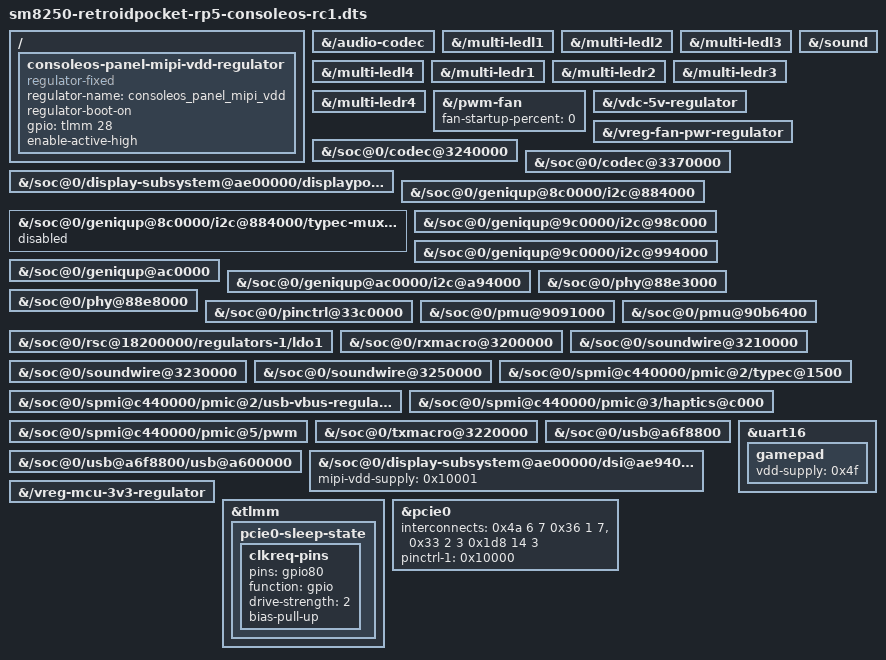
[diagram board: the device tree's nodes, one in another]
// SPDX-License-Identifier: BSD-3-Clause
/*
 * ConsoleOS RP5 release-candidate device tree.
 *
 * Start from the strict Phase 4A wireless + ADSP/PCIe-DRV source tree, then
 * enable exactly the peripherals present in the accepted Phase 4AT full-stack
 * DTB.  The sole power-policy delta is making the shared MCU/RGB/gamepad rail
 * controllable; userspace may then execute the validated Phase 4BE lifecycle.
 */

#include "sm8250-retroidpocket-rp5-phase4a-wireless-adsp-pcie-drv.dts"

/ {
	consoleos-panel-mipi-vdd-regulator {
		/* Keep every inherited RP5 phandle stable across this one-node delta. */
		phandle = <0x10001>;
		compatible = "regulator-fixed";
		regulator-name = "consoleos_panel_mipi_vdd";
		regulator-boot-on;
		gpio = <&tlmm 28 GPIO_ACTIVE_HIGH>;
		enable-active-high;
	};
};

&{/audio-codec} { status = "okay"; };
&{/multi-ledl1} { status = "okay"; };
&{/multi-ledl2} { status = "okay"; };
&{/multi-ledl3} { status = "okay"; };
&{/multi-ledl4} { status = "okay"; };
&{/multi-ledr1} { status = "okay"; };
&{/multi-ledr2} { status = "okay"; };
&{/multi-ledr3} { status = "okay"; };
&{/multi-ledr4} { status = "okay"; };
&{/pwm-fan} {
	status = "okay";
	/* Avoid ROCKNIX's fixed PWM 70 probe pulse on this handheld. */
	fan-startup-percent = <0>;
};
&{/sound} { status = "okay"; };
&{/vdc-5v-regulator} { status = "okay"; };
&{/vreg-fan-pwr-regulator} { status = "okay"; };

&{/soc@0/codec@3240000} { status = "okay"; };
&{/soc@0/codec@3370000} { status = "okay"; };
&{/soc@0/display-subsystem@ae00000/displayport-controller@ae90000} { status = "okay"; };
&{/soc@0/geniqup@8c0000/i2c@884000} { status = "okay"; };
&{/soc@0/geniqup@8c0000/i2c@884000/typec-mux@1c} { status = "disabled"; };
&{/soc@0/geniqup@9c0000/i2c@98c000} { status = "okay"; };
&{/soc@0/geniqup@9c0000/i2c@994000} { status = "okay"; };
&{/soc@0/geniqup@ac0000} { status = "okay"; };
&{/soc@0/geniqup@ac0000/i2c@a94000} { status = "okay"; };
&{/soc@0/phy@88e3000} { status = "okay"; };
&{/soc@0/phy@88e8000} { status = "okay"; };
&{/soc@0/pinctrl@33c0000} { status = "okay"; };
&{/soc@0/pmu@9091000} { status = "okay"; };
&{/soc@0/pmu@90b6400} { status = "okay"; };
&{/soc@0/rsc@18200000/regulators-1/ldo1} { status = "okay"; };
&{/soc@0/rxmacro@3200000} { status = "okay"; };
&{/soc@0/soundwire@3210000} { status = "okay"; };
&{/soc@0/soundwire@3230000} { status = "okay"; };
&{/soc@0/soundwire@3250000} { status = "okay"; };
&{/soc@0/spmi@c440000/pmic@2/typec@1500} { status = "okay"; };
&{/soc@0/spmi@c440000/pmic@2/usb-vbus-regulator@1100} { status = "okay"; };
&{/soc@0/spmi@c440000/pmic@3/haptics@c000} { status = "okay"; };
&{/soc@0/spmi@c440000/pmic@5/pwm} { status = "okay"; };
&{/soc@0/txmacro@3220000} { status = "okay"; };
&{/soc@0/usb@a6f8800} { status = "okay"; };
&{/soc@0/usb@a6f8800/usb@a600000} { status = "okay"; };

&{/soc@0/display-subsystem@ae00000/dsi@ae94000/panel@0} {
	/* Fixed above so this reference cannot renumber inherited phandles. */
	mipi-vdd-supply = <0x10001>;
};

&{/vreg-mcu-3v3-regulator} {
	/delete-property/ regulator-always-on;
};

&uart16 {
	gamepad {
		/* Keep the accepted RC17 DTB's existing phandle allocation stable. */
		vdd-supply = <0x4f>;
	};
};

&tlmm {
	pcie0-sleep-state {
		phandle = <0x10000>;

		clkreq-pins {
			pins = "gpio80";
			function = "gpio";
			drive-strength = <2>;
			bias-pull-up;
		};
	};
};

&pcie0 {
	/* Exact provider handles, endpoints and RPMh tags proven by Phase 4DU.
	 * Numeric cells keep the otherwise-identical release DTB's phandles stable.
	 */
	interconnects = <0x4a 6 7 0x36 1 7>,
			<0x33 2 3 0x1d8 14 3>;
	interconnect-names = "pcie-mem", "cpu-pcie";

	pinctrl-names = "default", "sleep";
	pinctrl-1 = <0x10000>;
};
